AUTOSAR XML (schema 00048)
package /MICROSAR/Csm_swc/DataTypes
  32 x impl type:
    Csm_ConfigIdType: range raw 0..65535, implementation-data-type=uint16  # The data type Csm_ConfigIdType identifies a configuration data set, which is unique within a service.
    dtRef_: implementation-data-type=uint8
    Csm_KeyDataType_StartApplication_CsmKey: category=ARRAY, sw-calibration-access=READ-ONLY  # Used as Buffer for service.
      element Csm_KeyDataType_StartApplication_CsmKeyElement: array-size=16, array-size-semantics=FIXED-SIZE, implementation-data-type=uint8
    Csm_PublicValueDataType_StartApplication_CsmKey: category=ARRAY, sw-calibration-access=READ-ONLY  # Used as Buffer for service.
      element Csm_PublicValueDataType_StartApplication_CsmKeyElement: array-size=16, array-size-semantics=FIXED-SIZE, implementation-data-type=uint8
    Csm_SeedDataTypeStartApplication_CsmKey: category=ARRAY, sw-calibration-access=READ-ONLY  # Used as Buffer for service.
      element Csm_SeedDataTypeStartApplication_CsmKeyElement: array-size=16, array-size-semantics=FIXED-SIZE, implementation-data-type=uint8
    Csm_DataPtr: category=DATA_REFERENCE, sw-pointer-target-props={target-category=TYPE_REFERENCE, implementation-data-type=uint8}
    Csm_const_DataPtr: category=DATA_REFERENCE, sw-pointer-target-props={target-category=TYPE_REFERENCE, implementation-data-type=uint8, sw-impl-policy=CONST}
    Crypto_ResultType: compu {1=E_NOT_OK, 2=CRYPTO_E_BUSY, 4=CRYPTO_E_ENTROPY_EXHAUSTED, 6=CRYPTO_E_KEY_READ_FAIL, 7=CRYPTO_E_KEY_WRITE_FAIL, 8=CRYPTO_E_KEY_NOT_AVAILABLE, 9=CRYPTO_E_KEY_NOT_VALID, 10=CRYPTO_E_KEY_SIZE_MISMATCH, 12=CRYPTO_E_JOB_CANCELED, 13=CRYPTO_E_KEY_EMPTY}, range raw 0..13, implementation-data-type=uint8  # Return for Std_ReturnType for Cryptostack.
    Csm_LengthPtr: category=DATA_REFERENCE, sw-pointer-target-props={target-category=TYPE_REFERENCE, implementation-data-type=uint32}
    Csm_VerifyResultPtr: category=DATA_REFERENCE, sw-pointer-target-props={target-category=TYPE_REFERENCE, implementation-data-type=Csm_VerifyResultType}
    Csm_ResultType: compu {1=E_NOT_OK, 2=E_SMALL_BUFFER, 3=E_ENTROPY_EXHAUSTION, 4=E_KEY_READ_FAIL, 5=E_KEY_NOT_AVAILABLE, 6=E_KEY_NOT_VALID, 7=E_JOB_CANCELED}, range raw 0..7, implementation-data-type=uint8  # Csm module specific return values for use in Std_ReturnType that could occur during asynchronous job processing.
    Csm_VerifyResultType: compu {0=CRYPTO_E_VER_OK, 1=CRYPTO_E_VER_NOT_OK}, range raw 0..1, implementation-data-type=uint8  # The data type Csm_VerifyResultType indicates the result of a verification operation.
    Crypto_OperationModeType: compu {1=CRYPTO_OPERATIONMODE_START, 2=CRYPTO_OPERATIONMODE_UPDATE, 3=CRYPTO_OPERATIONMODE_STREAMSTART, 4=CRYPTO_OPERATIONMODE_FINISH, 7=CRYPTO_OPERATIONMODE_SINGLECALL}, range raw 0..7, implementation-data-type=uint8  # Enum which operation shall be performed. This enum is constructed from a bit mask, where the first bit indicates “Start”, the second “Update” and the third “Finish”.
    Crypto_VerifyResultType: compu {0=CRYPTO_E_VER_OK, 1=CRYPTO_E_VER_NOT_OK}, range raw 0..1, implementation-data-type=uint8  # Enumeration of the result type of verification operations.
    Csm_KeyElementEnumType:  # Enum which lists the most common Crypto Key Elements IDs
      compu {1=CRYPTO_KE_MAC_KEY, 2=CRYPTO_KE_MAC_PROOF, 1=CRYPTO_KE_SIGNATURE_KEY, 29=CRYPTO_KE_SIGNATURE_CURVETYPE, 3=CRYPTO_KE_RANDOM_SEED_STATE, 4=CRYPTO_KE_RANDOM_ALGORITHM, 1=CRYPTO_KE_CIPHER_KEY, 5=CRYPTO_KE_CIPHER_IV, 6=CRYPTO_KE_CIPHER_PROOF, 7=CRYPTO_KE_CIPHER_2NDKEY, 8=CRYPTO_KE_KEYEXCHANGE_BASE, 9=CRYPTO_KE_KEYEXCHANGE_PRIVKEY, 10=CRYPTO_KE_KEYEXCHANGE_OWNPUBKEY, 1=CRYPTO_KE_KEYEXCHANGE_SHAREDVALUE, 1=CYRPTO_KE_KEYEXCHANGE_SHAREDVALUE, 12=CRYPTO_KE_KEYEXCHANGE_ALGORITHM, 29=CRYPTO_KE_KEYEXCHANGE_CURVETYPE, 1=CRYPTO_KE_KEYDERIVATION_PASSWORD, 13=CRYPTO_KE_KEYDERIVATION_SALT, 14=CRYPTO_KE_KEYDERIVATION_ITERATIONS, 15=CRYPTO_KE_KEYDERIVATION_ALGORITHM, 29=CRYPTO_KE_KEYDERIVATION_CURVETYPE, 1=CRYPTO_KE_KEYGENERATE_KEY, 16=CRYPTO_KE_KEYGENERATE_SEED, 17=CRYPTO_KE_KEYGENERATE_ALGORITHM, 29=CRYPTO_KE_KEYGENERATE_CURVETYPE, 0=CRYPTO_KE_CERTIFICATE_DATA, 18=CRYPTO_KE_CERTIFICATE_PARSING_FORMAT, 19=CRYPTO_KE_CERTIFICATE_CURRENT_TIME, 20=CRYPTO_KE_CERTIFICATE_VERSION, 21=CRYPTO_KE_CERTIFICATE_SERIALNUMBER, 22=CRYPTO_KE_CERTIFICATE_SIGNATURE_ALGORITHM, 23=CRYPTO_KE_CERTIFICATE_ISSUER, 24=CRYPTO_KE_CERTIFICATE_VALIDITY_NOT_BEFORE, 25=CRYPTO_KE_CERTIFICATE_VALIDITY_NOT_AFTER, 26=CRYPTO_KE_CERTIFICATE_SUBJECT, 1=CRYPTO_KE_CERTIFICATE_SUBJECT_PUBLIC_KEY, 27=CRYPTO_KE_CERTIFICATE_EXTENSIONS, 28=CRYPTO_KE_CERTIFICATE_SIGNATURE}
      range raw 0..4294967295
      implementation-data-type=uint32
    Csm_DecryptDataType_StartApplication_CsmPrimitives_AES_Decrypt: category=ARRAY, sw-calibration-access=READ-ONLY  # Used as Buffer for service.
      element Csm_DecryptDataType_StartApplication_CsmPrimitives_AES_DecryptElement: array-size=1024, array-size-semantics=FIXED-SIZE, implementation-data-type=uint8
    Csm_DecryptResultType_StartApplication_CsmPrimitives_AES_Decrypt: category=ARRAY, sw-calibration-access=READ-ONLY  # Used as Buffer for service.
      element Csm_DecryptResultType_StartApplication_CsmPrimitives_AES_DecryptElement: array-size=1024, array-size-semantics=FIXED-SIZE, implementation-data-type=uint8
    Csm_EncryptDataType_StartApplication_CsmPrimitives_AES_Encrypt: category=ARRAY, sw-calibration-access=READ-ONLY  # Used as Buffer for service.
      element Csm_EncryptDataType_StartApplication_CsmPrimitives_AES_EncryptElement: array-size=1024, array-size-semantics=FIXED-SIZE, implementation-data-type=uint8
    Csm_EncryptResultType_StartApplication_CsmPrimitives_AES_Encrypt: category=ARRAY, sw-calibration-access=READ-ONLY  # Used as Buffer for service.
      element Csm_EncryptResultType_StartApplication_CsmPrimitives_AES_EncryptElement: array-size=1024, array-size-semantics=FIXED-SIZE, implementation-data-type=uint8
    Csm_MacGenerateDataType_StartApplication_CsmPrimitives_MAC_Generate: category=ARRAY, sw-calibration-access=READ-ONLY  # Used as Buffer for service.
      element Csm_MacGenerateDataType_StartApplication_CsmPrimitives_MAC_GenerateElement: array-size=1024, array-size-semantics=FIXED-SIZE, implementation-data-type=uint8
    Csm_MacGenerateResultType_StartApplication_CsmPrimitives_MAC_Generate: category=ARRAY, sw-calibration-access=READ-ONLY  # Used as Buffer for service.
      element Csm_MacGenerateResultType_StartApplication_CsmPrimitives_MAC_GenerateElement: array-size=8, array-size-semantics=FIXED-SIZE, implementation-data-type=uint8
    Csm_MacVerifyDataType_StartApplication_CsmPrimitives_MAC_Verify: category=ARRAY, sw-calibration-access=READ-ONLY  # Used as Buffer for service.
      element Csm_MacVerifyDataType_StartApplication_CsmPrimitives_MAC_VerifyElement: array-size=1024, array-size-semantics=FIXED-SIZE, implementation-data-type=uint8
    Csm_MacVerifyCompareType_StartApplication_CsmPrimitives_MAC_Verify: category=ARRAY, sw-calibration-access=READ-ONLY  # Used as Buffer for service.
      element Csm_MacVerifyCompareType_StartApplication_CsmPrimitives_MAC_VerifyElement: array-size=1, array-size-semantics=FIXED-SIZE, implementation-data-type=uint8
    Csm_KeyDataType_StartApplication_CsmKey_Dec: category=ARRAY, sw-calibration-access=READ-ONLY  # Used as Buffer for service.
      element Csm_KeyDataType_StartApplication_CsmKey_DecElement: array-size=16, array-size-semantics=FIXED-SIZE, implementation-data-type=uint8
    Csm_PublicValueDataType_StartApplication_CsmKey_Dec: category=ARRAY, sw-calibration-access=READ-ONLY  # Used as Buffer for service.
      element Csm_PublicValueDataType_StartApplication_CsmKey_DecElement: array-size=16, array-size-semantics=FIXED-SIZE, implementation-data-type=uint8
    Csm_SeedDataTypeStartApplication_CsmKey_Dec: category=ARRAY, sw-calibration-access=READ-ONLY  # Used as Buffer for service.
      element Csm_SeedDataTypeStartApplication_CsmKey_DecElement: array-size=16, array-size-semantics=FIXED-SIZE, implementation-data-type=uint8
    Csm_KeyDataType_StartApplication_CsmKey_Enc: category=ARRAY, sw-calibration-access=READ-ONLY  # Used as Buffer for service.
      element Csm_KeyDataType_StartApplication_CsmKey_EncElement: array-size=16, array-size-semantics=FIXED-SIZE, implementation-data-type=uint8
    Csm_PublicValueDataType_StartApplication_CsmKey_Enc: category=ARRAY, sw-calibration-access=READ-ONLY  # Used as Buffer for service.
      element Csm_PublicValueDataType_StartApplication_CsmKey_EncElement: array-size=16, array-size-semantics=FIXED-SIZE, implementation-data-type=uint8
    Csm_SeedDataTypeStartApplication_CsmKey_Enc: category=ARRAY, sw-calibration-access=READ-ONLY  # Used as Buffer for service.
      element Csm_SeedDataTypeStartApplication_CsmKey_EncElement: array-size=16, array-size-semantics=FIXED-SIZE, implementation-data-type=uint8
    Csm_KeyDataType_StartApplication_CsmKey_MAC: category=ARRAY, sw-calibration-access=READ-ONLY  # Used as Buffer for service.
      element Csm_KeyDataType_StartApplication_CsmKey_MACElement: array-size=16, array-size-semantics=FIXED-SIZE, implementation-data-type=uint8
    Csm_PublicValueDataType_StartApplication_CsmKey_MAC: category=ARRAY, sw-calibration-access=READ-ONLY  # Used as Buffer for service.
      element Csm_PublicValueDataType_StartApplication_CsmKey_MACElement: array-size=16, array-size-semantics=FIXED-SIZE, implementation-data-type=uint8
    Csm_SeedDataTypeStartApplication_CsmKey_MAC: category=ARRAY, sw-calibration-access=READ-ONLY  # Used as Buffer for service.
      element Csm_SeedDataTypeStartApplication_CsmKey_MACElement: array-size=16, array-size-semantics=FIXED-SIZE, implementation-data-type=uint8
package /MICROSAR/Csm_swc/Interfaces
  8 x client server interface, all with is-service=true, service-kind=CRYPTO-SERVICE-MANAGER:
    CsmKeyManagement_StartApplication_CsmKey  # Interface to execute the key management functions.
      13 x operation:
        CertificateParse: possible-error=[CsmKeyManagement_StartApplication_CsmKey/E_NOT_OK, CsmKeyManagement_StartApplication_CsmKey/CSM_E_BUSY]  # This function shall dispatch the certificate parse function to the CRYIF.
        CertificateVerify: possible-error=[CsmKeyManagement_StartApplication_CsmKey/E_NOT_OK, CsmKeyManagement_StartApplication_CsmKey/CSM_E_BUSY]  # Verifies the certificate stored in the key referenced by verifyKeyId with the certificate stored in the key referenced by keyId. Note: Only certificates stored in the same Crypto Driver can be verified against each other. If the key element CRYPTO_KE_CERTIFICATE_CURRENT_TIME is used for the verification of the validity period of the certificate indentified by verifyKeyId, it shall have the same format as the timestamp in the certificate.
          arg verifyKeyId: type=uint32, direction=IN  # Holds the identifier of the key containing the certificate to be verified.
          arg verifyPtr: type=Crypto_VerifyResultType, direction=OUT  # Contains the result of the certificate verification.
        KeyCopy: possible-error=[CsmKeyManagement_StartApplication_CsmKey/E_NOT_OK, CsmKeyManagement_StartApplication_CsmKey/CSM_E_BUSY, CsmKeyManagement_StartApplication_CsmKey/CSM_E_SMALL_BUFFER, CsmKeyManagement_StartApplication_CsmKey/CSM_E_KEY_READ_FAIL, CsmKeyManagement_StartApplication_CsmKey/CSM_E_KEY_WRITE_FAIL, CsmKeyManagement_StartApplication_CsmKey/CSM_E_KEY_SIZE_MISMATCH]  # This function shall copy all key elements from the source key to a target key.
          arg targetKeyId: type=uint32, direction=IN  # Holds the identifier of the key whose key element shall be the destination element.
        KeyDerive: possible-error=CsmKeyManagement_StartApplication_CsmKey/E_NOT_OK  # Derives a new key by using the key elements in the given key. The given key contains the key elements for the password and salt. The derived key is stored in the key element with the id 1 of the key identified by targetCryptoKeyId.
          arg targetKeyId: type=uint32, direction=IN  # Holds the identifier of the key which is used to store the derived key.
        KeyElementCopy: possible-error=[CsmKeyManagement_StartApplication_CsmKey/E_NOT_OK, CsmKeyManagement_StartApplication_CsmKey/CSM_E_BUSY, CsmKeyManagement_StartApplication_CsmKey/CSM_E_SMALL_BUFFER, CsmKeyManagement_StartApplication_CsmKey/CSM_E_KEY_READ_FAIL, CsmKeyManagement_StartApplication_CsmKey/CSM_E_KEY_WRITE_FAIL, CsmKeyManagement_StartApplication_CsmKey/CSM_E_KEY_SIZE_MISMATCH]  # This function shall copy a key elements from one key to a target key.
          arg keyElementId: type=uint32, direction=IN  # Holds the identifier of the key element which shall be the source for the copy operation.
          arg targetKeyId: type=uint32, direction=IN  # Holds the identifier of the key whose key element shall be the destination element.
          arg targetKeyElementId: type=uint32, direction=IN  # Holds the identifier of the key element which shall be the destination for the copy operation.
        KeyElementGet: possible-error=[CsmKeyManagement_StartApplication_CsmKey/E_NOT_OK, CsmKeyManagement_StartApplication_CsmKey/CSM_E_BUSY, CsmKeyManagement_StartApplication_CsmKey/CSM_E_SMALL_BUFFER, CsmKeyManagement_StartApplication_CsmKey/CSM_E_KEY_READ_FAIL, CsmKeyManagement_StartApplication_CsmKey/CSM_E_KEY_NOT_AVAILABLE]  # Retrieves the key element bytes from a specific key element of the key and stores the key element in the provided buffer.
          arg keyElementId: type=uint32, direction=IN  # Holds the identifier of the key element to be read.
          arg keyPtr: type=Csm_KeyDataType_StartApplication_CsmKey, direction=OUT, server-argument-impl-policy=USE-ARRAY-BASE-TYPE  # Holds the data to the key element bytes to be written.
          arg keyLength: type=uint32, direction=OUT  # Contains the number of key element bytes.
        KeyElementSet: possible-error=[CsmKeyManagement_StartApplication_CsmKey/E_NOT_OK, CsmKeyManagement_StartApplication_CsmKey/CSM_E_BUSY, CsmKeyManagement_StartApplication_CsmKey/CSM_E_KEY_WRITE_FAIL, CsmKeyManagement_StartApplication_CsmKey/CSM_E_KEY_NOT_AVAILABLE, CsmKeyManagement_StartApplication_CsmKey/CSM_E_KEY_SIZE_MISMATCH]  # Sets the given key element bytes to the key.
          arg keyElementId: type=uint32, direction=IN  # Holds the identifier of the key element to be written.
          arg keyPtr: type=Csm_KeyDataType_StartApplication_CsmKey, direction=IN, server-argument-impl-policy=USE-ARRAY-BASE-TYPE  # Holds the data to the key element bytes to be processed.
          arg keyLength: type=uint32, direction=IN  # Contains the number of key element bytes.
        KeyExchangeCalcPubVal: possible-error=[CsmKeyManagement_StartApplication_CsmKey/E_NOT_OK, CsmKeyManagement_StartApplication_CsmKey/CSM_E_BUSY]  # Calculates the public value of the current user for the key exchange and stores the public key in the provided buffer.
          arg publicValuePtr: type=Csm_PublicValueDataType_StartApplication_CsmKey, direction=OUT, server-argument-impl-policy=USE-ARRAY-BASE-TYPE  # Holds a pointer to the memory location in which the public value length in bytes is stored. On calling this function, this parameter shall contain the size of the buffer in bytes provided by publicValuePtr. When the request has finished, the actual length of the returned value shall be stored.
          arg publicValueLengthPtr: type=uint32, direction=INOUT  # Contains the pointer to the data where the public value shall be stored.
        KeyExchangeCalcSecret: possible-error=[CsmKeyManagement_StartApplication_CsmKey/E_NOT_OK, CsmKeyManagement_StartApplication_CsmKey/CSM_E_BUSY]  # Calculates the shared secret key for the key exchange with the key material of the key identified by the keyId and the partner public key. The shared secret key is stored as a key element in the same key.
          arg partnerPublicValuePtr: type=Csm_PublicValueDataType_StartApplication_CsmKey, direction=IN, server-argument-impl-policy=USE-ARRAY-BASE-TYPE  # Holds the pointer to the memory location containing the partner's public value.
          arg partnerPublicValueLength: type=uint32, direction=IN  # Contains the number of bytes of the partner public value.
        KeyGenerate: possible-error=[CsmKeyManagement_StartApplication_CsmKey/E_NOT_OK, CsmKeyManagement_StartApplication_CsmKey/CSM_E_BUSY]  # Generates new key material and store it in the key identified by keyId.
        KeySetValid: possible-error=[CsmKeyManagement_StartApplication_CsmKey/E_NOT_OK, CsmKeyManagement_StartApplication_CsmKey/CSM_E_BUSY]  # Sets the given key element bytes to the key.
        RandomSeed: possible-error=[CsmKeyManagement_StartApplication_CsmKey/E_NOT_OK, CsmKeyManagement_StartApplication_CsmKey/CSM_E_BUSY]  # Feeds a key element with a random seed.
          arg seedPtr: type=Csm_SeedDataTypeStartApplication_CsmKey, direction=IN, server-argument-impl-policy=USE-ARRAY-BASE-TYPE  # Holds the data which shall be used for the random seed initialization.
          arg seedLength: type=uint32, direction=IN  # Contains the length of the seed in bytes.
        KeyElementCopyPartial: possible-error=[CsmKeyManagement_StartApplication_CsmKey/E_NOT_OK, CsmKeyManagement_StartApplication_CsmKey/CSM_E_BUSY, CsmKeyManagement_StartApplication_CsmKey/CSM_E_KEY_NOT_AVAILABLE, CsmKeyManagement_StartApplication_CsmKey/CSM_E_KEY_READ_FAIL, CsmKeyManagement_StartApplication_CsmKey/CSM_E_KEY_WRITE_FAIL, CsmKeyManagement_StartApplication_CsmKey/CSM_E_KEY_SIZE_MISMATCH, CsmKeyManagement_StartApplication_CsmKey/CSM_E_KEY_EMPTY]  # This function shall copy parts of a key element from one key to parts of a target key element of a target key.
          6 x arg, all with type=uint32, direction=IN:
            keyElementId  # Holds the identifier of the key element which shall be the source for the copy operation.
            keyElementSourceOffset  # This is the offset of the source key element indicating the start index of the copy operation.
            keyElementTargetOffset  # This is the offset of the destination key element indicating the start index of the copy operation.
            keyElementCopyLength  # Specifies the number of bytes that shall be copied.
            targetKeyId  # Holds the identifier of the key whose key element shall be the destination element.
            targetKeyElementId  # Holds the identifier of the key element which shall be the destination for the copy operation.
      8 x error:
        E_NOT_OK: error-code=1  # The service request failed.
        CSM_E_BUSY: error-code=2  # The service request failed because the service is still busy.
        CSM_E_SMALL_BUFFER: error-code=3  # The service request failed because the provided buffer is too small to store the result.
        CSM_E_KEY_READ_FAIL: error-code=6  # The service request failed because read access was denied.
        CSM_E_KEY_WRITE_FAIL: error-code=7  # The service request failed because write access was denied.
        CSM_E_KEY_NOT_AVAILABLE: error-code=8  # The service request failed because the key is not available.
        CSM_E_KEY_SIZE_MISMATCH: error-code=10  # The service request failed because the key element is not partially accessible and the provided key element length is too short or too long for that key element.
        CSM_E_KEY_EMPTY: error-code=13  # The service request failed because of uninitialized source key element.
    CsmKeyManagement_StartApplication_CsmKey_Dec  # Interface to execute the key management functions.
      13 x operation:
        CertificateParse: possible-error=[CsmKeyManagement_StartApplication_CsmKey_Dec/E_NOT_OK, CsmKeyManagement_StartApplication_CsmKey_Dec/CSM_E_BUSY]  # This function shall dispatch the certificate parse function to the CRYIF.
        CertificateVerify: possible-error=[CsmKeyManagement_StartApplication_CsmKey_Dec/E_NOT_OK, CsmKeyManagement_StartApplication_CsmKey_Dec/CSM_E_BUSY]  # Verifies the certificate stored in the key referenced by verifyKeyId with the certificate stored in the key referenced by keyId. Note: Only certificates stored in the same Crypto Driver can be verified against each other. If the key element CRYPTO_KE_CERTIFICATE_CURRENT_TIME is used for the verification of the validity period of the certificate indentified by verifyKeyId, it shall have the same format as the timestamp in the certificate.
          arg verifyKeyId: type=uint32, direction=IN  # Holds the identifier of the key containing the certificate to be verified.
          arg verifyPtr: type=Crypto_VerifyResultType, direction=OUT  # Contains the result of the certificate verification.
        KeyCopy: possible-error=[CsmKeyManagement_StartApplication_CsmKey_Dec/E_NOT_OK, CsmKeyManagement_StartApplication_CsmKey_Dec/CSM_E_BUSY, CsmKeyManagement_StartApplication_CsmKey_Dec/CSM_E_SMALL_BUFFER, CsmKeyManagement_StartApplication_CsmKey_Dec/CSM_E_KEY_READ_FAIL, CsmKeyManagement_StartApplication_CsmKey_Dec/CSM_E_KEY_WRITE_FAIL, CsmKeyManagement_StartApplication_CsmKey_Dec/CSM_E_KEY_SIZE_MISMATCH]  # This function shall copy all key elements from the source key to a target key.
          arg targetKeyId: type=uint32, direction=IN  # Holds the identifier of the key whose key element shall be the destination element.
        KeyDerive: possible-error=CsmKeyManagement_StartApplication_CsmKey_Dec/E_NOT_OK  # Derives a new key by using the key elements in the given key. The given key contains the key elements for the password and salt. The derived key is stored in the key element with the id 1 of the key identified by targetCryptoKeyId.
          arg targetKeyId: type=uint32, direction=IN  # Holds the identifier of the key which is used to store the derived key.
        KeyElementCopy: possible-error=[CsmKeyManagement_StartApplication_CsmKey_Dec/E_NOT_OK, CsmKeyManagement_StartApplication_CsmKey_Dec/CSM_E_BUSY, CsmKeyManagement_StartApplication_CsmKey_Dec/CSM_E_SMALL_BUFFER, CsmKeyManagement_StartApplication_CsmKey_Dec/CSM_E_KEY_READ_FAIL, CsmKeyManagement_StartApplication_CsmKey_Dec/CSM_E_KEY_WRITE_FAIL, CsmKeyManagement_StartApplication_CsmKey_Dec/CSM_E_KEY_SIZE_MISMATCH]  # This function shall copy a key elements from one key to a target key.
          arg keyElementId: type=uint32, direction=IN  # Holds the identifier of the key element which shall be the source for the copy operation.
          arg targetKeyId: type=uint32, direction=IN  # Holds the identifier of the key whose key element shall be the destination element.
          arg targetKeyElementId: type=uint32, direction=IN  # Holds the identifier of the key element which shall be the destination for the copy operation.
        KeyElementCopyPartial: possible-error=[CsmKeyManagement_StartApplication_CsmKey_Dec/E_NOT_OK, CsmKeyManagement_StartApplication_CsmKey_Dec/CSM_E_BUSY, CsmKeyManagement_StartApplication_CsmKey_Dec/CSM_E_KEY_NOT_AVAILABLE, CsmKeyManagement_StartApplication_CsmKey_Dec/CSM_E_KEY_READ_FAIL, CsmKeyManagement_StartApplication_CsmKey_Dec/CSM_E_KEY_WRITE_FAIL, CsmKeyManagement_StartApplication_CsmKey_Dec/CSM_E_KEY_SIZE_MISMATCH, CsmKeyManagement_StartApplication_CsmKey_Dec/CSM_E_KEY_EMPTY]  # This function shall copy parts of a key element from one key to parts of a target key element of a target key.
          6 x arg, all with type=uint32, direction=IN:
            keyElementId  # Holds the identifier of the key element which shall be the source for the copy operation.
            keyElementSourceOffset  # This is the offset of the source key element indicating the start index of the copy operation.
            keyElementTargetOffset  # This is the offset of the destination key element indicating the start index of the copy operation.
            keyElementCopyLength  # Specifies the number of bytes that shall be copied.
            targetKeyId  # Holds the identifier of the key whose key element shall be the destination element.
            targetKeyElementId  # Holds the identifier of the key element which shall be the destination for the copy operation.
        KeyElementGet: possible-error=[CsmKeyManagement_StartApplication_CsmKey_Dec/E_NOT_OK, CsmKeyManagement_StartApplication_CsmKey_Dec/CSM_E_BUSY, CsmKeyManagement_StartApplication_CsmKey_Dec/CSM_E_SMALL_BUFFER, CsmKeyManagement_StartApplication_CsmKey_Dec/CSM_E_KEY_READ_FAIL, CsmKeyManagement_StartApplication_CsmKey_Dec/CSM_E_KEY_NOT_AVAILABLE]  # Retrieves the key element bytes from a specific key element of the key and stores the key element in the provided buffer.
          arg keyElementId: type=uint32, direction=IN  # Holds the identifier of the key element to be read.
          arg keyPtr: type=Csm_KeyDataType_StartApplication_CsmKey_Dec, direction=OUT, server-argument-impl-policy=USE-ARRAY-BASE-TYPE  # Holds the data to the key element bytes to be written.
          arg keyLength: type=uint32, direction=OUT  # Contains the number of key element bytes.
        KeyElementSet: possible-error=[CsmKeyManagement_StartApplication_CsmKey_Dec/E_NOT_OK, CsmKeyManagement_StartApplication_CsmKey_Dec/CSM_E_BUSY, CsmKeyManagement_StartApplication_CsmKey_Dec/CSM_E_KEY_WRITE_FAIL, CsmKeyManagement_StartApplication_CsmKey_Dec/CSM_E_KEY_NOT_AVAILABLE, CsmKeyManagement_StartApplication_CsmKey_Dec/CSM_E_KEY_SIZE_MISMATCH]  # Sets the given key element bytes to the key.
          arg keyElementId: type=uint32, direction=IN  # Holds the identifier of the key element to be written.
          arg keyPtr: type=Csm_KeyDataType_StartApplication_CsmKey_Dec, direction=IN, server-argument-impl-policy=USE-ARRAY-BASE-TYPE  # Holds the data to the key element bytes to be processed.
          arg keyLength: type=uint32, direction=IN  # Contains the number of key element bytes.
        KeyExchangeCalcPubVal: possible-error=[CsmKeyManagement_StartApplication_CsmKey_Dec/E_NOT_OK, CsmKeyManagement_StartApplication_CsmKey_Dec/CSM_E_BUSY]  # Calculates the public value of the current user for the key exchange and stores the public key in the provided buffer.
          arg publicValuePtr: type=Csm_PublicValueDataType_StartApplication_CsmKey_Dec, direction=OUT, server-argument-impl-policy=USE-ARRAY-BASE-TYPE  # Holds a pointer to the memory location in which the public value length in bytes is stored. On calling this function, this parameter shall contain the size of the buffer in bytes provided by publicValuePtr. When the request has finished, the actual length of the returned value shall be stored.
          arg publicValueLengthPtr: type=uint32, direction=INOUT  # Contains the pointer to the data where the public value shall be stored.
        KeyExchangeCalcSecret: possible-error=[CsmKeyManagement_StartApplication_CsmKey_Dec/E_NOT_OK, CsmKeyManagement_StartApplication_CsmKey_Dec/CSM_E_BUSY]  # Calculates the shared secret key for the key exchange with the key material of the key identified by the keyId and the partner public key. The shared secret key is stored as a key element in the same key.
          arg partnerPublicValuePtr: type=Csm_PublicValueDataType_StartApplication_CsmKey_Dec, direction=IN, server-argument-impl-policy=USE-ARRAY-BASE-TYPE  # Holds the pointer to the memory location containing the partner's public value.
          arg partnerPublicValueLength: type=uint32, direction=IN  # Contains the number of bytes of the partner public value.
        KeyGenerate: possible-error=[CsmKeyManagement_StartApplication_CsmKey_Dec/E_NOT_OK, CsmKeyManagement_StartApplication_CsmKey_Dec/CSM_E_BUSY]  # Generates new key material and store it in the key identified by keyId.
        KeySetValid: possible-error=[CsmKeyManagement_StartApplication_CsmKey_Dec/E_NOT_OK, CsmKeyManagement_StartApplication_CsmKey_Dec/CSM_E_BUSY]  # Sets the given key element bytes to the key.
        RandomSeed: possible-error=[CsmKeyManagement_StartApplication_CsmKey_Dec/E_NOT_OK, CsmKeyManagement_StartApplication_CsmKey_Dec/CSM_E_BUSY]  # Feeds a key element with a random seed.
          arg seedPtr: type=Csm_SeedDataTypeStartApplication_CsmKey_Dec, direction=IN, server-argument-impl-policy=USE-ARRAY-BASE-TYPE  # Holds the data which shall be used for the random seed initialization.
          arg seedLength: type=uint32, direction=IN  # Contains the length of the seed in bytes.
      8 x error:
        E_NOT_OK: error-code=1  # The service request failed.
        CSM_E_BUSY: error-code=2  # The service request failed because the service is still busy.
        CSM_E_SMALL_BUFFER: error-code=3  # The service request failed because the provided buffer is too small to store the result.
        CSM_E_KEY_READ_FAIL: error-code=6  # The service request failed because read access was denied.
        CSM_E_KEY_WRITE_FAIL: error-code=7  # The service request failed because write access was denied.
        CSM_E_KEY_NOT_AVAILABLE: error-code=8  # The service request failed because the key is not available.
        CSM_E_KEY_SIZE_MISMATCH: error-code=10  # The service request failed because the key element is not partially accessible and the provided key element length is too short or too long for that key element.
        CSM_E_KEY_EMPTY: error-code=13  # The service request failed because of uninitialized source key element.
    CsmKeyManagement_StartApplication_CsmKey_Enc  # Interface to execute the key management functions.
      13 x operation:
        CertificateParse: possible-error=[CsmKeyManagement_StartApplication_CsmKey_Enc/E_NOT_OK, CsmKeyManagement_StartApplication_CsmKey_Enc/CSM_E_BUSY]  # This function shall dispatch the certificate parse function to the CRYIF.
        CertificateVerify: possible-error=[CsmKeyManagement_StartApplication_CsmKey_Enc/E_NOT_OK, CsmKeyManagement_StartApplication_CsmKey_Enc/CSM_E_BUSY]  # Verifies the certificate stored in the key referenced by verifyKeyId with the certificate stored in the key referenced by keyId. Note: Only certificates stored in the same Crypto Driver can be verified against each other. If the key element CRYPTO_KE_CERTIFICATE_CURRENT_TIME is used for the verification of the validity period of the certificate indentified by verifyKeyId, it shall have the same format as the timestamp in the certificate.
          arg verifyKeyId: type=uint32, direction=IN  # Holds the identifier of the key containing the certificate to be verified.
          arg verifyPtr: type=Crypto_VerifyResultType, direction=OUT  # Contains the result of the certificate verification.
        KeyCopy: possible-error=[CsmKeyManagement_StartApplication_CsmKey_Enc/E_NOT_OK, CsmKeyManagement_StartApplication_CsmKey_Enc/CSM_E_BUSY, CsmKeyManagement_StartApplication_CsmKey_Enc/CSM_E_SMALL_BUFFER, CsmKeyManagement_StartApplication_CsmKey_Enc/CSM_E_KEY_READ_FAIL, CsmKeyManagement_StartApplication_CsmKey_Enc/CSM_E_KEY_WRITE_FAIL, CsmKeyManagement_StartApplication_CsmKey_Enc/CSM_E_KEY_SIZE_MISMATCH]  # This function shall copy all key elements from the source key to a target key.
          arg targetKeyId: type=uint32, direction=IN  # Holds the identifier of the key whose key element shall be the destination element.
        KeyDerive: possible-error=CsmKeyManagement_StartApplication_CsmKey_Enc/E_NOT_OK  # Derives a new key by using the key elements in the given key. The given key contains the key elements for the password and salt. The derived key is stored in the key element with the id 1 of the key identified by targetCryptoKeyId.
          arg targetKeyId: type=uint32, direction=IN  # Holds the identifier of the key which is used to store the derived key.
        KeyElementCopy: possible-error=[CsmKeyManagement_StartApplication_CsmKey_Enc/E_NOT_OK, CsmKeyManagement_StartApplication_CsmKey_Enc/CSM_E_BUSY, CsmKeyManagement_StartApplication_CsmKey_Enc/CSM_E_SMALL_BUFFER, CsmKeyManagement_StartApplication_CsmKey_Enc/CSM_E_KEY_READ_FAIL, CsmKeyManagement_StartApplication_CsmKey_Enc/CSM_E_KEY_WRITE_FAIL, CsmKeyManagement_StartApplication_CsmKey_Enc/CSM_E_KEY_SIZE_MISMATCH]  # This function shall copy a key elements from one key to a target key.
          arg keyElementId: type=uint32, direction=IN  # Holds the identifier of the key element which shall be the source for the copy operation.
          arg targetKeyId: type=uint32, direction=IN  # Holds the identifier of the key whose key element shall be the destination element.
          arg targetKeyElementId: type=uint32, direction=IN  # Holds the identifier of the key element which shall be the destination for the copy operation.
        KeyElementCopyPartial: possible-error=[CsmKeyManagement_StartApplication_CsmKey_Enc/E_NOT_OK, CsmKeyManagement_StartApplication_CsmKey_Enc/CSM_E_BUSY, CsmKeyManagement_StartApplication_CsmKey_Enc/CSM_E_KEY_NOT_AVAILABLE, CsmKeyManagement_StartApplication_CsmKey_Enc/CSM_E_KEY_READ_FAIL, CsmKeyManagement_StartApplication_CsmKey_Enc/CSM_E_KEY_WRITE_FAIL, CsmKeyManagement_StartApplication_CsmKey_Enc/CSM_E_KEY_SIZE_MISMATCH, CsmKeyManagement_StartApplication_CsmKey_Enc/CSM_E_KEY_EMPTY]  # This function shall copy parts of a key element from one key to parts of a target key element of a target key.
          6 x arg, all with type=uint32, direction=IN:
            keyElementId  # Holds the identifier of the key element which shall be the source for the copy operation.
            keyElementSourceOffset  # This is the offset of the source key element indicating the start index of the copy operation.
            keyElementTargetOffset  # This is the offset of the destination key element indicating the start index of the copy operation.
            keyElementCopyLength  # Specifies the number of bytes that shall be copied.
            targetKeyId  # Holds the identifier of the key whose key element shall be the destination element.
            targetKeyElementId  # Holds the identifier of the key element which shall be the destination for the copy operation.
        KeyElementGet: possible-error=[CsmKeyManagement_StartApplication_CsmKey_Enc/E_NOT_OK, CsmKeyManagement_StartApplication_CsmKey_Enc/CSM_E_BUSY, CsmKeyManagement_StartApplication_CsmKey_Enc/CSM_E_SMALL_BUFFER, CsmKeyManagement_StartApplication_CsmKey_Enc/CSM_E_KEY_READ_FAIL, CsmKeyManagement_StartApplication_CsmKey_Enc/CSM_E_KEY_NOT_AVAILABLE]  # Retrieves the key element bytes from a specific key element of the key and stores the key element in the provided buffer.
          arg keyElementId: type=uint32, direction=IN  # Holds the identifier of the key element to be read.
          arg keyPtr: type=Csm_KeyDataType_StartApplication_CsmKey_Enc, direction=OUT, server-argument-impl-policy=USE-ARRAY-BASE-TYPE  # Holds the data to the key element bytes to be written.
          arg keyLength: type=uint32, direction=OUT  # Contains the number of key element bytes.
        KeyElementSet: possible-error=[CsmKeyManagement_StartApplication_CsmKey_Enc/E_NOT_OK, CsmKeyManagement_StartApplication_CsmKey_Enc/CSM_E_BUSY, CsmKeyManagement_StartApplication_CsmKey_Enc/CSM_E_KEY_WRITE_FAIL, CsmKeyManagement_StartApplication_CsmKey_Enc/CSM_E_KEY_NOT_AVAILABLE, CsmKeyManagement_StartApplication_CsmKey_Enc/CSM_E_KEY_SIZE_MISMATCH]  # Sets the given key element bytes to the key.
          arg keyElementId: type=uint32, direction=IN  # Holds the identifier of the key element to be written.
          arg keyPtr: type=Csm_KeyDataType_StartApplication_CsmKey_Enc, direction=IN, server-argument-impl-policy=USE-ARRAY-BASE-TYPE  # Holds the data to the key element bytes to be processed.
          arg keyLength: type=uint32, direction=IN  # Contains the number of key element bytes.
        KeyExchangeCalcPubVal: possible-error=[CsmKeyManagement_StartApplication_CsmKey_Enc/E_NOT_OK, CsmKeyManagement_StartApplication_CsmKey_Enc/CSM_E_BUSY]  # Calculates the public value of the current user for the key exchange and stores the public key in the provided buffer.
          arg publicValuePtr: type=Csm_PublicValueDataType_StartApplication_CsmKey_Enc, direction=OUT, server-argument-impl-policy=USE-ARRAY-BASE-TYPE  # Holds a pointer to the memory location in which the public value length in bytes is stored. On calling this function, this parameter shall contain the size of the buffer in bytes provided by publicValuePtr. When the request has finished, the actual length of the returned value shall be stored.
          arg publicValueLengthPtr: type=uint32, direction=INOUT  # Contains the pointer to the data where the public value shall be stored.
        KeyExchangeCalcSecret: possible-error=[CsmKeyManagement_StartApplication_CsmKey_Enc/E_NOT_OK, CsmKeyManagement_StartApplication_CsmKey_Enc/CSM_E_BUSY]  # Calculates the shared secret key for the key exchange with the key material of the key identified by the keyId and the partner public key. The shared secret key is stored as a key element in the same key.
          arg partnerPublicValuePtr: type=Csm_PublicValueDataType_StartApplication_CsmKey_Enc, direction=IN, server-argument-impl-policy=USE-ARRAY-BASE-TYPE  # Holds the pointer to the memory location containing the partner's public value.
          arg partnerPublicValueLength: type=uint32, direction=IN  # Contains the number of bytes of the partner public value.
        KeyGenerate: possible-error=[CsmKeyManagement_StartApplication_CsmKey_Enc/E_NOT_OK, CsmKeyManagement_StartApplication_CsmKey_Enc/CSM_E_BUSY]  # Generates new key material and store it in the key identified by keyId.
        KeySetValid: possible-error=[CsmKeyManagement_StartApplication_CsmKey_Enc/E_NOT_OK, CsmKeyManagement_StartApplication_CsmKey_Enc/CSM_E_BUSY]  # Sets the given key element bytes to the key.
        RandomSeed: possible-error=[CsmKeyManagement_StartApplication_CsmKey_Enc/E_NOT_OK, CsmKeyManagement_StartApplication_CsmKey_Enc/CSM_E_BUSY]  # Feeds a key element with a random seed.
          arg seedPtr: type=Csm_SeedDataTypeStartApplication_CsmKey_Enc, direction=IN, server-argument-impl-policy=USE-ARRAY-BASE-TYPE  # Holds the data which shall be used for the random seed initialization.
          arg seedLength: type=uint32, direction=IN  # Contains the length of the seed in bytes.
      8 x error:
        E_NOT_OK: error-code=1  # The service request failed.
        CSM_E_BUSY: error-code=2  # The service request failed because the service is still busy.
        CSM_E_SMALL_BUFFER: error-code=3  # The service request failed because the provided buffer is too small to store the result.
        CSM_E_KEY_READ_FAIL: error-code=6  # The service request failed because read access was denied.
        CSM_E_KEY_WRITE_FAIL: error-code=7  # The service request failed because write access was denied.
        CSM_E_KEY_NOT_AVAILABLE: error-code=8  # The service request failed because the key is not available.
        CSM_E_KEY_SIZE_MISMATCH: error-code=10  # The service request failed because the key element is not partially accessible and the provided key element length is too short or too long for that key element.
        CSM_E_KEY_EMPTY: error-code=13  # The service request failed because of uninitialized source key element.
    CsmKeyManagement_StartApplication_CsmKey_MAC  # Interface to execute the key management functions.
      13 x operation:
        CertificateParse: possible-error=[CsmKeyManagement_StartApplication_CsmKey_MAC/E_NOT_OK, CsmKeyManagement_StartApplication_CsmKey_MAC/CSM_E_BUSY]  # This function shall dispatch the certificate parse function to the CRYIF.
        CertificateVerify: possible-error=[CsmKeyManagement_StartApplication_CsmKey_MAC/E_NOT_OK, CsmKeyManagement_StartApplication_CsmKey_MAC/CSM_E_BUSY]  # Verifies the certificate stored in the key referenced by verifyKeyId with the certificate stored in the key referenced by keyId. Note: Only certificates stored in the same Crypto Driver can be verified against each other. If the key element CRYPTO_KE_CERTIFICATE_CURRENT_TIME is used for the verification of the validity period of the certificate indentified by verifyKeyId, it shall have the same format as the timestamp in the certificate.
          arg verifyKeyId: type=uint32, direction=IN  # Holds the identifier of the key containing the certificate to be verified.
          arg verifyPtr: type=Crypto_VerifyResultType, direction=OUT  # Contains the result of the certificate verification.
        KeyCopy: possible-error=[CsmKeyManagement_StartApplication_CsmKey_MAC/E_NOT_OK, CsmKeyManagement_StartApplication_CsmKey_MAC/CSM_E_BUSY, CsmKeyManagement_StartApplication_CsmKey_MAC/CSM_E_SMALL_BUFFER, CsmKeyManagement_StartApplication_CsmKey_MAC/CSM_E_KEY_READ_FAIL, CsmKeyManagement_StartApplication_CsmKey_MAC/CSM_E_KEY_WRITE_FAIL, CsmKeyManagement_StartApplication_CsmKey_MAC/CSM_E_KEY_SIZE_MISMATCH]  # This function shall copy all key elements from the source key to a target key.
          arg targetKeyId: type=uint32, direction=IN  # Holds the identifier of the key whose key element shall be the destination element.
        KeyDerive: possible-error=CsmKeyManagement_StartApplication_CsmKey_MAC/E_NOT_OK  # Derives a new key by using the key elements in the given key. The given key contains the key elements for the password and salt. The derived key is stored in the key element with the id 1 of the key identified by targetCryptoKeyId.
          arg targetKeyId: type=uint32, direction=IN  # Holds the identifier of the key which is used to store the derived key.
        KeyElementCopy: possible-error=[CsmKeyManagement_StartApplication_CsmKey_MAC/E_NOT_OK, CsmKeyManagement_StartApplication_CsmKey_MAC/CSM_E_BUSY, CsmKeyManagement_StartApplication_CsmKey_MAC/CSM_E_SMALL_BUFFER, CsmKeyManagement_StartApplication_CsmKey_MAC/CSM_E_KEY_READ_FAIL, CsmKeyManagement_StartApplication_CsmKey_MAC/CSM_E_KEY_WRITE_FAIL, CsmKeyManagement_StartApplication_CsmKey_MAC/CSM_E_KEY_SIZE_MISMATCH]  # This function shall copy a key elements from one key to a target key.
          arg keyElementId: type=uint32, direction=IN  # Holds the identifier of the key element which shall be the source for the copy operation.
          arg targetKeyId: type=uint32, direction=IN  # Holds the identifier of the key whose key element shall be the destination element.
          arg targetKeyElementId: type=uint32, direction=IN  # Holds the identifier of the key element which shall be the destination for the copy operation.
        KeyElementCopyPartial: possible-error=[CsmKeyManagement_StartApplication_CsmKey_MAC/E_NOT_OK, CsmKeyManagement_StartApplication_CsmKey_MAC/CSM_E_BUSY, CsmKeyManagement_StartApplication_CsmKey_MAC/CSM_E_KEY_NOT_AVAILABLE, CsmKeyManagement_StartApplication_CsmKey_MAC/CSM_E_KEY_READ_FAIL, CsmKeyManagement_StartApplication_CsmKey_MAC/CSM_E_KEY_WRITE_FAIL, CsmKeyManagement_StartApplication_CsmKey_MAC/CSM_E_KEY_SIZE_MISMATCH, CsmKeyManagement_StartApplication_CsmKey_MAC/CSM_E_KEY_EMPTY]  # This function shall copy parts of a key element from one key to parts of a target key element of a target key.
          6 x arg, all with type=uint32, direction=IN:
            keyElementId  # Holds the identifier of the key element which shall be the source for the copy operation.
            keyElementSourceOffset  # This is the offset of the source key element indicating the start index of the copy operation.
            keyElementTargetOffset  # This is the offset of the destination key element indicating the start index of the copy operation.
            keyElementCopyLength  # Specifies the number of bytes that shall be copied.
            targetKeyId  # Holds the identifier of the key whose key element shall be the destination element.
            targetKeyElementId  # Holds the identifier of the key element which shall be the destination for the copy operation.
        KeyElementGet: possible-error=[CsmKeyManagement_StartApplication_CsmKey_MAC/E_NOT_OK, CsmKeyManagement_StartApplication_CsmKey_MAC/CSM_E_BUSY, CsmKeyManagement_StartApplication_CsmKey_MAC/CSM_E_SMALL_BUFFER, CsmKeyManagement_StartApplication_CsmKey_MAC/CSM_E_KEY_READ_FAIL, CsmKeyManagement_StartApplication_CsmKey_MAC/CSM_E_KEY_NOT_AVAILABLE]  # Retrieves the key element bytes from a specific key element of the key and stores the key element in the provided buffer.
          arg keyElementId: type=uint32, direction=IN  # Holds the identifier of the key element to be read.
          arg keyPtr: type=Csm_KeyDataType_StartApplication_CsmKey_MAC, direction=OUT, server-argument-impl-policy=USE-ARRAY-BASE-TYPE  # Holds the data to the key element bytes to be written.
          arg keyLength: type=uint32, direction=OUT  # Contains the number of key element bytes.
        KeyElementSet: possible-error=[CsmKeyManagement_StartApplication_CsmKey_MAC/E_NOT_OK, CsmKeyManagement_StartApplication_CsmKey_MAC/CSM_E_BUSY, CsmKeyManagement_StartApplication_CsmKey_MAC/CSM_E_KEY_WRITE_FAIL, CsmKeyManagement_StartApplication_CsmKey_MAC/CSM_E_KEY_NOT_AVAILABLE, CsmKeyManagement_StartApplication_CsmKey_MAC/CSM_E_KEY_SIZE_MISMATCH]  # Sets the given key element bytes to the key.
          arg keyElementId: type=uint32, direction=IN  # Holds the identifier of the key element to be written.
          arg keyPtr: type=Csm_KeyDataType_StartApplication_CsmKey_MAC, direction=IN, server-argument-impl-policy=USE-ARRAY-BASE-TYPE  # Holds the data to the key element bytes to be processed.
          arg keyLength: type=uint32, direction=IN  # Contains the number of key element bytes.
        KeyExchangeCalcPubVal: possible-error=[CsmKeyManagement_StartApplication_CsmKey_MAC/E_NOT_OK, CsmKeyManagement_StartApplication_CsmKey_MAC/CSM_E_BUSY]  # Calculates the public value of the current user for the key exchange and stores the public key in the provided buffer.
          arg publicValuePtr: type=Csm_PublicValueDataType_StartApplication_CsmKey_MAC, direction=OUT, server-argument-impl-policy=USE-ARRAY-BASE-TYPE  # Holds a pointer to the memory location in which the public value length in bytes is stored. On calling this function, this parameter shall contain the size of the buffer in bytes provided by publicValuePtr. When the request has finished, the actual length of the returned value shall be stored.
          arg publicValueLengthPtr: type=uint32, direction=INOUT  # Contains the pointer to the data where the public value shall be stored.
        KeyExchangeCalcSecret: possible-error=[CsmKeyManagement_StartApplication_CsmKey_MAC/E_NOT_OK, CsmKeyManagement_StartApplication_CsmKey_MAC/CSM_E_BUSY]  # Calculates the shared secret key for the key exchange with the key material of the key identified by the keyId and the partner public key. The shared secret key is stored as a key element in the same key.
          arg partnerPublicValuePtr: type=Csm_PublicValueDataType_StartApplication_CsmKey_MAC, direction=IN, server-argument-impl-policy=USE-ARRAY-BASE-TYPE  # Holds the pointer to the memory location containing the partner's public value.
          arg partnerPublicValueLength: type=uint32, direction=IN  # Contains the number of bytes of the partner public value.
        KeyGenerate: possible-error=[CsmKeyManagement_StartApplication_CsmKey_MAC/E_NOT_OK, CsmKeyManagement_StartApplication_CsmKey_MAC/CSM_E_BUSY]  # Generates new key material and store it in the key identified by keyId.
        KeySetValid: possible-error=[CsmKeyManagement_StartApplication_CsmKey_MAC/E_NOT_OK, CsmKeyManagement_StartApplication_CsmKey_MAC/CSM_E_BUSY]  # Sets the given key element bytes to the key.
        RandomSeed: possible-error=[CsmKeyManagement_StartApplication_CsmKey_MAC/E_NOT_OK, CsmKeyManagement_StartApplication_CsmKey_MAC/CSM_E_BUSY]  # Feeds a key element with a random seed.
          arg seedPtr: type=Csm_SeedDataTypeStartApplication_CsmKey_MAC, direction=IN, server-argument-impl-policy=USE-ARRAY-BASE-TYPE  # Holds the data which shall be used for the random seed initialization.
          arg seedLength: type=uint32, direction=IN  # Contains the length of the seed in bytes.
      8 x error:
        E_NOT_OK: error-code=1  # The service request failed.
        CSM_E_BUSY: error-code=2  # The service request failed because the service is still busy.
        CSM_E_SMALL_BUFFER: error-code=3  # The service request failed because the provided buffer is too small to store the result.
        CSM_E_KEY_READ_FAIL: error-code=6  # The service request failed because read access was denied.
        CSM_E_KEY_WRITE_FAIL: error-code=7  # The service request failed because write access was denied.
        CSM_E_KEY_NOT_AVAILABLE: error-code=8  # The service request failed because the key is not available.
        CSM_E_KEY_SIZE_MISMATCH: error-code=10  # The service request failed because the key element is not partially accessible and the provided key element length is too short or too long for that key element.
        CSM_E_KEY_EMPTY: error-code=13  # The service request failed because of uninitialized source key element.
    CsmDecrypt_StartApplication_CsmPrimitives_AES_Decrypt  # This interface is used to perform the decryption.
      operation Decrypt: possible-error=[CsmDecrypt_StartApplication_CsmPrimitives_AES_Decrypt/E_NOT_OK, CsmDecrypt_StartApplication_CsmPrimitives_AES_Decrypt/CSM_E_BUSY, CsmDecrypt_StartApplication_CsmPrimitives_AES_Decrypt/CSM_E_SMALL_BUFFER, CsmDecrypt_StartApplication_CsmPrimitives_AES_Decrypt/CSM_E_KEY_NOT_VALID, CsmDecrypt_StartApplication_CsmPrimitives_AES_Decrypt/CSM_E_KEY_SIZE_MISMATCH, CsmDecrypt_StartApplication_CsmPrimitives_AES_Decrypt/CSM_E_KEY_EMPTY]  # This interface shall be used to start the Decrypt service of the CSM module.
        4 x arg:
          dataBuffer: type=Csm_DecryptDataType_StartApplication_CsmPrimitives_AES_Decrypt, direction=IN, server-argument-impl-policy=USE-ARRAY-BASE-TYPE  # Holds a pointer to the data for which a plaintext shall be computed.
          dataLength: type=uint32, direction=IN  # Contains the number of bytes for which the plaintext shall be computed.
          resultBuffer: type=Csm_DecryptResultType_StartApplication_CsmPrimitives_AES_Decrypt, direction=OUT, server-argument-impl-policy=USE-ARRAY-BASE-TYPE  # Holds a pointer to the memory location which will hold the plaintext. The memory location must have at least the given length.
          resultLength: type=uint32, direction=INOUT  # Holds a pointer to the memory location in which the length information is stored. On calling this function this parameter shall contain the size of the provided buffer. When the request has finished, the actual length of the returned plaintext shall be stored.
      operation CancelJob: possible-error=[CsmDecrypt_StartApplication_CsmPrimitives_AES_Decrypt/E_NOT_OK, CsmDecrypt_StartApplication_CsmPrimitives_AES_Decrypt/CSM_E_JOB_CANCELED]  # Cancels the Job.
      7 x error:
        E_NOT_OK: error-code=1  # The service request failed.
        CSM_E_BUSY: error-code=2  # The service request failed because the service is still busy.
        CSM_E_SMALL_BUFFER: error-code=3  # The service request failed because the provided buffer is too small to store the result.
        CSM_E_KEY_NOT_VALID: error-code=9  # The service request failed because the key is not valid.
        CSM_E_KEY_SIZE_MISMATCH: error-code=10  # The service request failed because the key element is not partially accessible and the provided key element length is too short or too long for that key element.
        CSM_E_KEY_EMPTY: error-code=13  # The service request failed because of uninitialized source key element.
        CSM_E_JOB_CANCELED: error-code=12  # The job has been marked to be aborted at the next opportunity. It will be further processed until the job finish notification.
    CsmEncrypt_StartApplication_CsmPrimitives_AES_Encrypt  # This interface is used to perform the encryption.
      operation Encrypt: possible-error=[CsmEncrypt_StartApplication_CsmPrimitives_AES_Encrypt/E_NOT_OK, CsmEncrypt_StartApplication_CsmPrimitives_AES_Encrypt/CSM_E_BUSY, CsmEncrypt_StartApplication_CsmPrimitives_AES_Encrypt/CSM_E_SMALL_BUFFER, CsmEncrypt_StartApplication_CsmPrimitives_AES_Encrypt/CSM_E_KEY_NOT_VALID, CsmEncrypt_StartApplication_CsmPrimitives_AES_Encrypt/CSM_E_KEY_SIZE_MISMATCH, CsmEncrypt_StartApplication_CsmPrimitives_AES_Encrypt/CSM_E_KEY_EMPTY]  # This interface shall be used to start the Encrypt service of the CSM module.
        4 x arg:
          dataBuffer: type=Csm_EncryptDataType_StartApplication_CsmPrimitives_AES_Encrypt, direction=IN, server-argument-impl-policy=USE-ARRAY-BASE-TYPE  # Holds a pointer to the data for which a ciphertext shall be computed.
          dataLength: type=uint32, direction=IN  # Contains the number of bytes for which the ciphertext shall be computed.
          resultBuffer: type=Csm_EncryptResultType_StartApplication_CsmPrimitives_AES_Encrypt, direction=OUT, server-argument-impl-policy=USE-ARRAY-BASE-TYPE  # Holds a pointer to the memory location which will hold the ciphertext. The memory location must have at least the given length.
          resultLength: type=uint32, direction=INOUT  # Holds a pointer to the memory location in which the length information is stored. On calling this function this parameter shall contain the size of the provided buffer. When the request has finished, the actual length of the returned ciphertext shall be stored.
      operation CancelJob: possible-error=[CsmEncrypt_StartApplication_CsmPrimitives_AES_Encrypt/E_NOT_OK, CsmEncrypt_StartApplication_CsmPrimitives_AES_Encrypt/CSM_E_JOB_CANCELED]  # Cancels the Job.
      7 x error:
        E_NOT_OK: error-code=1  # The service request failed.
        CSM_E_BUSY: error-code=2  # The service request failed because the service is still busy.
        CSM_E_SMALL_BUFFER: error-code=3  # The service request failed because the provided buffer is too small to store the result.
        CSM_E_KEY_NOT_VALID: error-code=9  # The service request failed because the key is not valid.
        CSM_E_KEY_SIZE_MISMATCH: error-code=10  # The service request failed because the key element is not partially accessible and the provided key element length is too short or too long for that key element.
        CSM_E_KEY_EMPTY: error-code=13  # The service request failed because of uninitialized source key element.
        CSM_E_JOB_CANCELED: error-code=12  # The job has been marked to be aborted at the next opportunity. It will be further processed until the job finish notification.
    CsmMacGenerate_StartApplication_CsmPrimitives_MAC_Generate  # A message authentication code (MAC) is a short piece of information used to authenticate a message. A MAC algorithm accepts as input a secret key and an arbitrary-length message to be authenticated, and outputs a MAC. The MAC value protects both a message's data integrity as well as its authenticity, by allowing verifiers (who also possess the secret key) to detect any changes to the message content.
      operation MacGenerate: possible-error=[CsmMacGenerate_StartApplication_CsmPrimitives_MAC_Generate/E_NOT_OK, CsmMacGenerate_StartApplication_CsmPrimitives_MAC_Generate/CSM_E_BUSY, CsmMacGenerate_StartApplication_CsmPrimitives_MAC_Generate/CSM_E_SMALL_BUFFER]  # This interface shall be used to start the MAC generation service of the CSM module.
        4 x arg:
          dataBuffer: type=Csm_MacGenerateDataType_StartApplication_CsmPrimitives_MAC_Generate, direction=IN, server-argument-impl-policy=USE-ARRAY-BASE-TYPE  # Holds a pointer to the data for which a MAC shall be computed.
          dataLength: type=uint32, direction=IN  # Contains the number of bytes for which the MAC shall be computed.
          resultBuffer: type=Csm_MacGenerateResultType_StartApplication_CsmPrimitives_MAC_Generate, direction=OUT, server-argument-impl-policy=USE-ARRAY-BASE-TYPE  # Holds a pointer to the memory location which will hold the MAC. The memory location must have at least the given length.
          resultLength: type=uint32, direction=INOUT  # Holds a pointer to the memory location in which the length information is stored. On calling this function this parameter shall contain the size of the provided buffer. When the request has finished, the actual length of the returned MAC shall be stored.
      operation CancelJob: possible-error=CsmMacGenerate_StartApplication_CsmPrimitives_MAC_Generate/E_NOT_OK  # Cancels the Job.
      error E_NOT_OK: error-code=1  # The service request failed.
      error CSM_E_BUSY: error-code=2  # The service request failed because the service is still busy.
      error CSM_E_SMALL_BUFFER: error-code=3  # The service request failed because the provided buffer is too small to store the result.
    CsmMacVerify_StartApplication_CsmPrimitives_MAC_Verify  # A message authentication code (MAC) is a short piece of information used to authenticate a message. A MAC algorithm accepts as input a secret key and an arbitrary-length message to be authenticated, and outputs a MAC. The MAC value protects both a message's data integrity as well as its authenticity, by allowing verifiers (who also possess the secret key) to detect any changes to the message content.
      operation MacVerify: possible-error=[CsmMacVerify_StartApplication_CsmPrimitives_MAC_Verify/E_NOT_OK, CsmMacVerify_StartApplication_CsmPrimitives_MAC_Verify/CSM_E_BUSY, CsmMacVerify_StartApplication_CsmPrimitives_MAC_Verify/CSM_E_SMALL_BUFFER]  # This interface shall be used to start the MAC verification service of the CSM module.
        5 x arg:
          dataBuffer: type=Csm_MacVerifyDataType_StartApplication_CsmPrimitives_MAC_Verify, direction=IN, server-argument-impl-policy=USE-ARRAY-BASE-TYPE  # Holds a pointer to the data for which a MAC shall be computed.
          dataLength: type=uint32, direction=IN  # Contains the number of bytes for which the MAC shall be computed.
          compareBuffer: type=Csm_MacVerifyCompareType_StartApplication_CsmPrimitives_MAC_Verify, direction=IN, server-argument-impl-policy=USE-ARRAY-BASE-TYPE  # Contains the MAC to be verified.
          compareLength: type=uint32, direction=IN  # Contains the length of the MAC to be verified in BITS.
          verifyResult: type=Crypto_VerifyResultType, direction=OUT  # Holds a pointer to the memory location which will hold the result of the MAC verification
      operation CancelJob: possible-error=CsmMacVerify_StartApplication_CsmPrimitives_MAC_Verify/E_NOT_OK  # Cancels the Job.
      error E_NOT_OK: error-code=1  # The service request failed.
      error CSM_E_BUSY: error-code=2  # The service request failed because the service is still busy.
      error CSM_E_SMALL_BUFFER: error-code=3  # The service request failed because the provided buffer is too small to store the result.
package /MICROSAR/Csm_swc/ComponentTypes
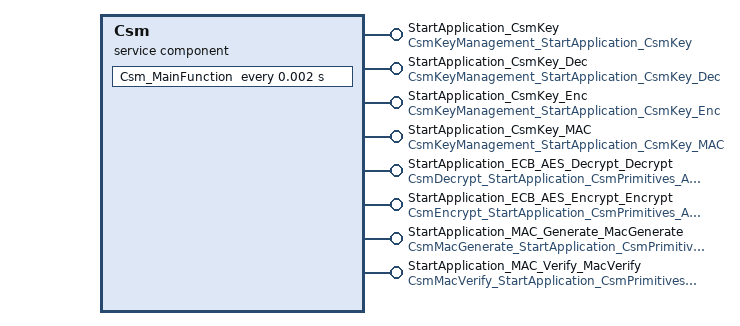
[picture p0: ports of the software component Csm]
  service sw component type Csm: category=SERVICE_COMPONENT
    8 x provide port:
      StartApplication_CsmKey: provided-interface=CsmKeyManagement_StartApplication_CsmKey
      StartApplication_CsmKey_Dec: provided-interface=CsmKeyManagement_StartApplication_CsmKey_Dec
      StartApplication_CsmKey_Enc: provided-interface=CsmKeyManagement_StartApplication_CsmKey_Enc
      StartApplication_CsmKey_MAC: provided-interface=CsmKeyManagement_StartApplication_CsmKey_MAC
      StartApplication_ECB_AES_Decrypt_Decrypt: provided-interface=CsmDecrypt_StartApplication_CsmPrimitives_AES_Decrypt
      StartApplication_ECB_AES_Encrypt_Encrypt: provided-interface=CsmEncrypt_StartApplication_CsmPrimitives_AES_Encrypt
      StartApplication_MAC_Generate_MacGenerate: provided-interface=CsmMacGenerate_StartApplication_CsmPrimitives_MAC_Generate
      StartApplication_MAC_Verify_MacVerify: provided-interface=CsmMacVerify_StartApplication_CsmPrimitives_MAC_Verify
    behavior CsmInternalBehavior: handle-termination-and-restart=NO-SUPPORT, included-data-type-set=data-type=[Csm_VerifyResultType, Csm_ConfigIdType, Crypto_OperationModeType, Crypto_VerifyResultType, Csm_KeyElementEnumType, Csm_ResultType, Crypto_ResultType, Csm_KeyDataType_StartApplication_CsmKey_Dec, Csm_PublicValueDataType_StartApplication_CsmKey_Dec, Csm_SeedDataTypeStartApplication_CsmKey_Dec, Csm_KeyDataType_StartApplication_CsmKey_Enc, Csm_PublicValueDataType_StartApplication_CsmKey_Enc, Csm_SeedDataTypeStartApplication_CsmKey_Enc, Csm_KeyDataType_StartApplication_CsmKey_MAC, Csm_PublicValueDataType_StartApplication_CsmKey_MAC, Csm_SeedDataTypeStartApplication_CsmKey_MAC, Csm_KeyDataType_StartApplication_CsmKey, Csm_PublicValueDataType_StartApplication_CsmKey, Csm_SeedDataTypeStartApplication_CsmKey, Csm_DecryptDataType_StartApplication_CsmPrimitives_AES_Decrypt, Csm_DecryptResultType_StartApplication_CsmPrimitives_AES_Decrypt, Csm_EncryptDataType_StartApplication_CsmPrimitives_AES_Encrypt, Csm_EncryptResultType_StartApplication_CsmPrimitives_AES_Encrypt, Csm_MacGenerateDataType_StartApplication_CsmPrimitives_MAC_Generate, Csm_MacGenerateResultType_StartApplication_CsmPrimitives_MAC_Generate, Csm_MacVerifyDataType_StartApplication_CsmPrimitives_MAC_Verify, Csm_MacVerifyCompareType_StartApplication_CsmPrimitives_MAC_Verify]
      timing event Timer_Csm_MainFunction: start-on-event=Csm_MainFunction, period=0.002
      60 x operation invoked event:
        OpEventKeyElementSet_KeyElementSet_StartApplication_CsmKey: start-on-event=KeyElementSet, operation=StartApplication_CsmKey.KeyElementSet
        OpEventKeySetValid_KeySetValid_StartApplication_CsmKey: start-on-event=KeySetValid, operation=StartApplication_CsmKey.KeySetValid
        OpEventRandomSeed_RandomSeed_StartApplication_CsmKey: start-on-event=RandomSeed, operation=StartApplication_CsmKey.RandomSeed
        OpEventKeyElementCopyPartial_KeyElementCopyPartial_StartApplication_CsmKey: start-on-event=KeyElementCopyPartial, operation=StartApplication_CsmKey.KeyElementCopyPartial
        OpEventKeyGenerate43x_KeyGenerate_StartApplication_CsmKey: start-on-event=KeyGenerate43x, operation=StartApplication_CsmKey.KeyGenerate
        OpEventKeyElementCopy43x_KeyElementCopy_StartApplication_CsmKey: start-on-event=KeyElementCopy43x, operation=StartApplication_CsmKey.KeyElementCopy
        OpEventKeyExchangeCalcPubVal43x_KeyExchangeCalcPubVal_StartApplication_CsmKey: start-on-event=KeyExchangeCalcPubVal43x, operation=StartApplication_CsmKey.KeyExchangeCalcPubVal
        OpEventCertificateVerify43x_CertificateVerify_StartApplication_CsmKey: start-on-event=CertificateVerify43x, operation=StartApplication_CsmKey.CertificateVerify
        OpEventKeyElementGet43x_KeyElementGet_StartApplication_CsmKey: start-on-event=KeyElementGet43x, operation=StartApplication_CsmKey.KeyElementGet
        OpEventKeyDerive43x_KeyDerive_StartApplication_CsmKey: start-on-event=KeyDerive43x, operation=StartApplication_CsmKey.KeyDerive
        OpEventCertificateParse43x_CertificateParse_StartApplication_CsmKey: start-on-event=CertificateParse43x, operation=StartApplication_CsmKey.CertificateParse
        OpEventKeyCopy43x_KeyCopy_StartApplication_CsmKey: start-on-event=KeyCopy43x, operation=StartApplication_CsmKey.KeyCopy
        OpEventKeyExchangeCalcSecret43x_KeyExchangeCalcSecret_StartApplication_CsmKey: start-on-event=KeyExchangeCalcSecret43x, operation=StartApplication_CsmKey.KeyExchangeCalcSecret
        OpEventKeyGenerate43x_KeyGenerate_StartApplication_CsmKey_Enc: start-on-event=KeyGenerate43x, operation=StartApplication_CsmKey_Enc.KeyGenerate
        OpEventKeyGenerate43x_KeyGenerate_StartApplication_CsmKey_Dec: start-on-event=KeyGenerate43x, operation=StartApplication_CsmKey_Dec.KeyGenerate
        OpEventKeyGenerate43x_KeyGenerate_StartApplication_CsmKey_MAC: start-on-event=KeyGenerate43x, operation=StartApplication_CsmKey_MAC.KeyGenerate
        OpEventKeyElementSet_KeyElementSet_StartApplication_CsmKey_Dec: start-on-event=KeyElementSet, operation=StartApplication_CsmKey_Dec.KeyElementSet
        OpEventKeyElementSet_KeyElementSet_StartApplication_CsmKey_Enc: start-on-event=KeyElementSet, operation=StartApplication_CsmKey_Enc.KeyElementSet
        OpEventKeyElementSet_KeyElementSet_StartApplication_CsmKey_MAC: start-on-event=KeyElementSet, operation=StartApplication_CsmKey_MAC.KeyElementSet
        OpEventCertificateVerify43x_CertificateVerify_StartApplication_CsmKey_Enc: start-on-event=CertificateVerify43x, operation=StartApplication_CsmKey_Enc.CertificateVerify
        OpEventCertificateVerify43x_CertificateVerify_StartApplication_CsmKey_MAC: start-on-event=CertificateVerify43x, operation=StartApplication_CsmKey_MAC.CertificateVerify
        OpEventCertificateVerify43x_CertificateVerify_StartApplication_CsmKey_Dec: start-on-event=CertificateVerify43x, operation=StartApplication_CsmKey_Dec.CertificateVerify
        OpEventMacVerify43x_MacVerify_StartApplication_MAC_Verify_MacVerify: start-on-event=MacVerify43x, operation=StartApplication_MAC_Verify_MacVerify.MacVerify
        OpEventKeyElementCopy43x_KeyElementCopy_StartApplication_CsmKey_MAC: start-on-event=KeyElementCopy43x, operation=StartApplication_CsmKey_MAC.KeyElementCopy
        OpEventKeyElementCopy43x_KeyElementCopy_StartApplication_CsmKey_Dec: start-on-event=KeyElementCopy43x, operation=StartApplication_CsmKey_Dec.KeyElementCopy
        OpEventKeyElementCopy43x_KeyElementCopy_StartApplication_CsmKey_Enc: start-on-event=KeyElementCopy43x, operation=StartApplication_CsmKey_Enc.KeyElementCopy
        OpEventCancelJob43x_CancelJob_StartApplication_MAC_Verify_MacVerify: start-on-event=CancelJob43x, operation=StartApplication_MAC_Verify_MacVerify.CancelJob
        OpEventCancelJob43x_CancelJob_StartApplication_MAC_Generate_MacGenerate: start-on-event=CancelJob43x, operation=StartApplication_MAC_Generate_MacGenerate.CancelJob
        OpEventKeyElementGet43x_KeyElementGet_StartApplication_CsmKey_MAC: start-on-event=KeyElementGet43x, operation=StartApplication_CsmKey_MAC.KeyElementGet
        OpEventKeyElementGet43x_KeyElementGet_StartApplication_CsmKey_Dec: start-on-event=KeyElementGet43x, operation=StartApplication_CsmKey_Dec.KeyElementGet
        OpEventKeyElementGet43x_KeyElementGet_StartApplication_CsmKey_Enc: start-on-event=KeyElementGet43x, operation=StartApplication_CsmKey_Enc.KeyElementGet
        OpEventRandomSeed_RandomSeed_StartApplication_CsmKey_Enc: start-on-event=RandomSeed, operation=StartApplication_CsmKey_Enc.RandomSeed
        OpEventRandomSeed_RandomSeed_StartApplication_CsmKey_MAC: start-on-event=RandomSeed, operation=StartApplication_CsmKey_MAC.RandomSeed
        OpEventRandomSeed_RandomSeed_StartApplication_CsmKey_Dec: start-on-event=RandomSeed, operation=StartApplication_CsmKey_Dec.RandomSeed
        OpEventKeyElementCopyPartial_KeyElementCopyPartial_StartApplication_CsmKey_MAC: start-on-event=KeyElementCopyPartial, operation=StartApplication_CsmKey_MAC.KeyElementCopyPartial
        OpEventKeyElementCopyPartial_KeyElementCopyPartial_StartApplication_CsmKey_Dec: start-on-event=KeyElementCopyPartial, operation=StartApplication_CsmKey_Dec.KeyElementCopyPartial
        OpEventKeyElementCopyPartial_KeyElementCopyPartial_StartApplication_CsmKey_Enc: start-on-event=KeyElementCopyPartial, operation=StartApplication_CsmKey_Enc.KeyElementCopyPartial
        OpEventCertificateParse43x_CertificateParse_StartApplication_CsmKey_MAC: start-on-event=CertificateParse43x, operation=StartApplication_CsmKey_MAC.CertificateParse
        OpEventCertificateParse43x_CertificateParse_StartApplication_CsmKey_Dec: start-on-event=CertificateParse43x, operation=StartApplication_CsmKey_Dec.CertificateParse
        OpEventCertificateParse43x_CertificateParse_StartApplication_CsmKey_Enc: start-on-event=CertificateParse43x, operation=StartApplication_CsmKey_Enc.CertificateParse
        OpEventKeyCopy43x_KeyCopy_StartApplication_CsmKey_Dec: start-on-event=KeyCopy43x, operation=StartApplication_CsmKey_Dec.KeyCopy
        OpEventKeyCopy43x_KeyCopy_StartApplication_CsmKey_Enc: start-on-event=KeyCopy43x, operation=StartApplication_CsmKey_Enc.KeyCopy
        OpEventKeyCopy43x_KeyCopy_StartApplication_CsmKey_MAC: start-on-event=KeyCopy43x, operation=StartApplication_CsmKey_MAC.KeyCopy
        OpEventKeyExchangeCalcPubVal43x_KeyExchangeCalcPubVal_StartApplication_CsmKey_Dec: start-on-event=KeyExchangeCalcPubVal43x, operation=StartApplication_CsmKey_Dec.KeyExchangeCalcPubVal
        OpEventKeyExchangeCalcPubVal43x_KeyExchangeCalcPubVal_StartApplication_CsmKey_MAC: start-on-event=KeyExchangeCalcPubVal43x, operation=StartApplication_CsmKey_MAC.KeyExchangeCalcPubVal
        OpEventKeyExchangeCalcPubVal43x_KeyExchangeCalcPubVal_StartApplication_CsmKey_Enc: start-on-event=KeyExchangeCalcPubVal43x, operation=StartApplication_CsmKey_Enc.KeyExchangeCalcPubVal
        OpEventKeyDerive43x_KeyDerive_StartApplication_CsmKey_Enc: start-on-event=KeyDerive43x, operation=StartApplication_CsmKey_Enc.KeyDerive
        OpEventKeyDerive43x_KeyDerive_StartApplication_CsmKey_Dec: start-on-event=KeyDerive43x, operation=StartApplication_CsmKey_Dec.KeyDerive
        OpEventKeyDerive43x_KeyDerive_StartApplication_CsmKey_MAC: start-on-event=KeyDerive43x, operation=StartApplication_CsmKey_MAC.KeyDerive
        OpEventKeySetValid_KeySetValid_StartApplication_CsmKey_Enc: start-on-event=KeySetValid, operation=StartApplication_CsmKey_Enc.KeySetValid
        OpEventKeySetValid_KeySetValid_StartApplication_CsmKey_MAC: start-on-event=KeySetValid, operation=StartApplication_CsmKey_MAC.KeySetValid
        OpEventKeySetValid_KeySetValid_StartApplication_CsmKey_Dec: start-on-event=KeySetValid, operation=StartApplication_CsmKey_Dec.KeySetValid
        OpEventEncrypt_Encrypt_StartApplication_ECB_AES_Encrypt_Encrypt: start-on-event=Encrypt, operation=StartApplication_ECB_AES_Encrypt_Encrypt.Encrypt
        OpEventCancelJob_CancelJob_StartApplication_ECB_AES_Encrypt_Encrypt: start-on-event=CancelJob, operation=StartApplication_ECB_AES_Encrypt_Encrypt.CancelJob
        OpEventCancelJob_CancelJob_StartApplication_ECB_AES_Decrypt_Decrypt: start-on-event=CancelJob, operation=StartApplication_ECB_AES_Decrypt_Decrypt.CancelJob
        OpEventKeyExchangeCalcSecret43x_KeyExchangeCalcSecret_StartApplication_CsmKey_Enc: start-on-event=KeyExchangeCalcSecret43x, operation=StartApplication_CsmKey_Enc.KeyExchangeCalcSecret
        OpEventKeyExchangeCalcSecret43x_KeyExchangeCalcSecret_StartApplication_CsmKey_Dec: start-on-event=KeyExchangeCalcSecret43x, operation=StartApplication_CsmKey_Dec.KeyExchangeCalcSecret
        OpEventKeyExchangeCalcSecret43x_KeyExchangeCalcSecret_StartApplication_CsmKey_MAC: start-on-event=KeyExchangeCalcSecret43x, operation=StartApplication_CsmKey_MAC.KeyExchangeCalcSecret
        OpEventMacGenerate43x_MacGenerate_StartApplication_MAC_Generate_MacGenerate: start-on-event=MacGenerate43x, operation=StartApplication_MAC_Generate_MacGenerate.MacGenerate
        OpEventDecrypt_Decrypt_StartApplication_ECB_AES_Decrypt_Decrypt: start-on-event=Decrypt, operation=StartApplication_ECB_AES_Decrypt_Decrypt.Decrypt
      port-api-options:
        {enable-take-address=true, indirect-api=false, port-arg-values=[{value=25, value-type=uint32}, {value=7, value-type=Crypto_OperationModeType}], port=StartApplication_ECB_AES_Decrypt_Decrypt}
        {enable-take-address=true, indirect-api=false, port-arg-values=[{value=26, value-type=uint32}, {value=7, value-type=Crypto_OperationModeType}], port=StartApplication_ECB_AES_Encrypt_Encrypt}
        {enable-take-address=true, indirect-api=false, port-arg-values=[{value=27, value-type=uint32}, {value=7, value-type=Crypto_OperationModeType}], port=StartApplication_MAC_Generate_MacGenerate}
        {enable-take-address=true, indirect-api=false, port-arg-values=[{value=28, value-type=uint32}, {value=7, value-type=Crypto_OperationModeType}], port=StartApplication_MAC_Verify_MacVerify}
        {enable-take-address=true, indirect-api=false, port-defined-argument-value{value=keyId:30, value-type=uint32}, port=StartApplication_CsmKey_Dec}
        {enable-take-address=true, indirect-api=false, port-defined-argument-value{value=keyId:31, value-type=uint32}, port=StartApplication_CsmKey_Enc}
        {enable-take-address=true, indirect-api=false, port-defined-argument-value{value=keyId:32, value-type=uint32}, port=StartApplication_CsmKey_MAC}
        {enable-take-address=true, indirect-api=false, port-defined-argument-value{value=keyId:29, value-type=uint32}, port=StartApplication_CsmKey}
      20 x runnable:
        Csm_MainFunction
        KeyElementSet: can-be-invoked-concurrently=true, symbol=Csm_KeyElementSet
        KeySetValid: can-be-invoked-concurrently=true, symbol=Csm_KeySetValid
        RandomSeed: can-be-invoked-concurrently=true, symbol=Csm_RandomSeed
        KeyElementCopyPartial: can-be-invoked-concurrently=true, symbol=Csm_KeyElementCopyPartial
        KeyGenerate43x: can-be-invoked-concurrently=true, symbol=Csm_KeyGenerate43x
        KeyElementCopy43x: can-be-invoked-concurrently=true, symbol=Csm_KeyElementCopy43x
        KeyExchangeCalcPubVal43x: can-be-invoked-concurrently=true, symbol=Csm_KeyExchangeCalcPubVal43x
        CertificateVerify43x: can-be-invoked-concurrently=true, symbol=Csm_CertificateVerify43x
        KeyElementGet43x: can-be-invoked-concurrently=true, symbol=Csm_KeyElementGet43x
        KeyDerive43x: can-be-invoked-concurrently=true, symbol=Csm_KeyDerive43x
        CertificateParse43x: can-be-invoked-concurrently=true, symbol=Csm_CertificateParse43x
        KeyCopy43x: can-be-invoked-concurrently=true, symbol=Csm_KeyCopy43x
        KeyExchangeCalcSecret43x: can-be-invoked-concurrently=true, symbol=Csm_KeyExchangeCalcSecret43x
        MacVerify43x: can-be-invoked-concurrently=true, symbol=Csm_MacVerify43x
        CancelJob43x: can-be-invoked-concurrently=true, symbol=Csm_CancelJob43x
        Encrypt: can-be-invoked-concurrently=true, symbol=Csm_Encrypt
        CancelJob: can-be-invoked-concurrently=true, symbol=Csm_CancelJob
        MacGenerate43x: can-be-invoked-concurrently=true, symbol=Csm_MacGenerate43x
        Decrypt: can-be-invoked-concurrently=true, symbol=Csm_Decrypt
  swc implementation CsmImplementation: programming-language=C, behavior=CsmInternalBehavior
